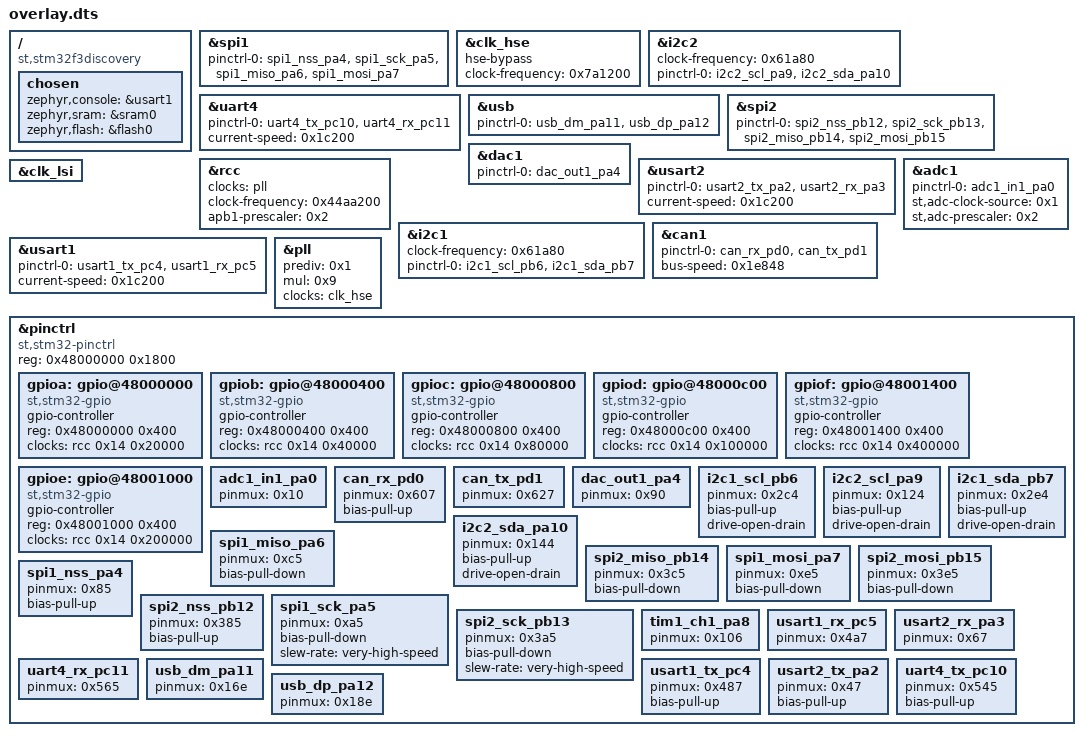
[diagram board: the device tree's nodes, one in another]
/ {
	compatible = "st,stm32f3discovery";
	chosen {
		zephyr,console = &usart1;
		zephyr,sram = &sram0;
		zephyr,flash = &flash0;
	};
};
&spi1{
	status = "okay";
	pinctrl-0 = < &spi1_nss_pa4 &spi1_sck_pa5 &spi1_miso_pa6 &spi1_mosi_pa7 >;
	pinctrl-names = "default";
};
&clk_hse{
	status = "okay";
	hse-bypass;
	clock-frequency = < 0x7a1200 >;
};
&i2c2{
	clock-frequency = < 0x61a80 >;
	status = "okay";
	pinctrl-0 = < &i2c2_scl_pa9 &i2c2_sda_pa10 >;
	pinctrl-names = "default";
};
&uart4{
	status = "okay";
	pinctrl-0 = < &uart4_tx_pc10 &uart4_rx_pc11 >;
	pinctrl-names = "default";
	current-speed = < 0x1c200 >;
};
&usb{
	status = "okay";
	pinctrl-0 = < &usb_dm_pa11 &usb_dp_pa12 >;
	pinctrl-names = "default";
};
&spi2{
	status = "okay";
	pinctrl-0 = < &spi2_nss_pb12 &spi2_sck_pb13 &spi2_miso_pb14 &spi2_mosi_pb15 >;
	pinctrl-names = "default";
};
&dac1{
	status = "okay";
	pinctrl-0 = < &dac_out1_pa4 >;
	pinctrl-names = "default";
};
&rcc{
	clocks = < &pll >;
	clock-frequency = < 0x44aa200 >;
	apb1-prescaler = < 0x2 >;
};
&usart2{
	status = "okay";
	pinctrl-0 = < &usart2_tx_pa2 &usart2_rx_pa3 >;
	pinctrl-names = "default";
	current-speed = < 0x1c200 >;
};
&adc1{
	status = "okay";
	pinctrl-0 = < &adc1_in1_pa0 >;
	pinctrl-names = "default";
	st,adc-clock-source = < 0x1 >;
	st,adc-prescaler = < 0x2 >;
};
&i2c1{
	clock-frequency = < 0x61a80 >;
	status = "okay";
	pinctrl-0 = < &i2c1_scl_pb6 &i2c1_sda_pb7 >;
	pinctrl-names = "default";
};
&clk_lsi{
	status = "okay";
};
&can1{
	status = "okay";
	pinctrl-0 = < &can_rx_pd0 &can_tx_pd1 >;
	pinctrl-names = "default";
	bus-speed = < 0x1e848 >;
};
&usart1{
	status = "okay";
	pinctrl-0 = < &usart1_tx_pc4 &usart1_rx_pc5 >;
	pinctrl-names = "default";
	current-speed = < 0x1c200 >;
};
&pll{
	status = "okay";
	prediv = < 0x1 >;
	mul = < 0x9 >;
	clocks = < &clk_hse >;
};
&pinctrl{
	compatible = "st,stm32-pinctrl";
	#address-cells = < 0x1 >;
	#size-cells = < 0x1 >;
	reg = < 0x48000000 0x1800 >;
	gpioa: gpio@48000000 {
		compatible = "st,stm32-gpio";
		gpio-controller;
		#gpio-cells = < 0x2 >;
		reg = < 0x48000000 0x400 >;
		clocks = < &rcc 0x14 0x20000 >;
	};
	gpiob: gpio@48000400 {
		compatible = "st,stm32-gpio";
		gpio-controller;
		#gpio-cells = < 0x2 >;
		reg = < 0x48000400 0x400 >;
		clocks = < &rcc 0x14 0x40000 >;
	};
	gpioc: gpio@48000800 {
		compatible = "st,stm32-gpio";
		gpio-controller;
		#gpio-cells = < 0x2 >;
		reg = < 0x48000800 0x400 >;
		clocks = < &rcc 0x14 0x80000 >;
	};
	gpiod: gpio@48000c00 {
		compatible = "st,stm32-gpio";
		gpio-controller;
		#gpio-cells = < 0x2 >;
		reg = < 0x48000c00 0x400 >;
		clocks = < &rcc 0x14 0x100000 >;
	};
	gpiof: gpio@48001400 {
		compatible = "st,stm32-gpio";
		gpio-controller;
		#gpio-cells = < 0x2 >;
		reg = < 0x48001400 0x400 >;
		clocks = < &rcc 0x14 0x400000 >;
	};
	gpioe: gpio@48001000 {
		compatible = "st,stm32-gpio";
		gpio-controller;
		#gpio-cells = < 0x2 >;
		reg = < 0x48001000 0x400 >;
		clocks = < &rcc 0x14 0x200000 >;
	};
	adc1_in1_pa0: adc1_in1_pa0 {
		pinmux = < 0x10 >;
	};
	can_rx_pd0: can_rx_pd0 {
		pinmux = < 0x607 >;
		bias-pull-up;
	};
	can_tx_pd1: can_tx_pd1 {
		pinmux = < 0x627 >;
	};
	dac_out1_pa4: dac_out1_pa4 {
		pinmux = < 0x90 >;
	};
	i2c1_scl_pb6: i2c1_scl_pb6 {
		pinmux = < 0x2c4 >;
		bias-pull-up;
		drive-open-drain;
	};
	i2c2_scl_pa9: i2c2_scl_pa9 {
		pinmux = < 0x124 >;
		bias-pull-up;
		drive-open-drain;
	};
	i2c1_sda_pb7: i2c1_sda_pb7 {
		pinmux = < 0x2e4 >;
		bias-pull-up;
		drive-open-drain;
	};
	i2c2_sda_pa10: i2c2_sda_pa10 {
		pinmux = < 0x144 >;
		bias-pull-up;
		drive-open-drain;
	};
	spi1_miso_pa6: spi1_miso_pa6 {
		pinmux = < 0xc5 >;
		bias-pull-down;
	};
	spi2_miso_pb14: spi2_miso_pb14 {
		pinmux = < 0x3c5 >;
		bias-pull-down;
	};
	spi1_mosi_pa7: spi1_mosi_pa7 {
		pinmux = < 0xe5 >;
		bias-pull-down;
	};
	spi2_mosi_pb15: spi2_mosi_pb15 {
		pinmux = < 0x3e5 >;
		bias-pull-down;
	};
	spi1_nss_pa4: spi1_nss_pa4 {
		pinmux = < 0x85 >;
		bias-pull-up;
	};
	spi2_nss_pb12: spi2_nss_pb12 {
		pinmux = < 0x385 >;
		bias-pull-up;
	};
	spi1_sck_pa5: spi1_sck_pa5 {
		pinmux = < 0xa5 >;
		bias-pull-down;
		slew-rate = "very-high-speed";
	};
	spi2_sck_pb13: spi2_sck_pb13 {
		pinmux = < 0x3a5 >;
		bias-pull-down;
		slew-rate = "very-high-speed";
	};
	tim1_ch1_pa8: tim1_ch1_pa8 {
		pinmux = < 0x106 >;
	};
	usart1_rx_pc5: usart1_rx_pc5 {
		pinmux = < 0x4a7 >;
	};
	usart2_rx_pa3: usart2_rx_pa3 {
		pinmux = < 0x67 >;
	};
	uart4_rx_pc11: uart4_rx_pc11 {
		pinmux = < 0x565 >;
	};
	usart1_tx_pc4: usart1_tx_pc4 {
		pinmux = < 0x487 >;
		bias-pull-up;
	};
	usart2_tx_pa2: usart2_tx_pa2 {
		pinmux = < 0x47 >;
		bias-pull-up;
	};
	uart4_tx_pc10: uart4_tx_pc10 {
		pinmux = < 0x545 >;
		bias-pull-up;
	};
	usb_dm_pa11: usb_dm_pa11 {
		pinmux = < 0x16e >;
	};
	usb_dp_pa12: usb_dp_pa12 {
		pinmux = < 0x18e >;
	};
};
